AUTOSAR XML (schema 4-2-2)
package /Components
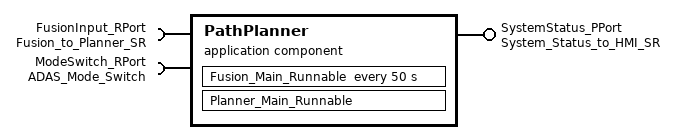
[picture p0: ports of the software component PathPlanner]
  application sw component type PathPlanner
    provide port SystemStatus_PPort: provided-interface=System_Status_to_HMI_SR
    provide/require port Actuation_ClientPort: provided-required-interface=Planner_to_Actuation_CS
    provide/require port Parameter_ClientPort: provided-required-interface=Parameter_Service_CS
    require port FusionInput_RPort: required-interface=Fusion_to_Planner_SR
    require port ModeSwitch_RPort: required-interface=ADAS_Mode_Switch
    behavior PathPlanner_Behavior
      external trigger occurred event Emergency_Brake_Trigger: start-on-event=Fusion_Main_Runnable
      swc mode switch event Mode_Switch_Requested: start-on-event=Fusion_Main_Runnable, activation=onModeRequest, mode=ADASModeGroup.ModeSwitch_RPort.ADASModeDeclaration
      timing event Planner_Cycle: start-on-event=Fusion_Main_Runnable, period=50
      runnable Planner_Main_Runnable: minimum-start-interval=25, symbol=PathPlanner_Planner_Main
        data-receive-point-by-values:
          access Access_FusedObjectList: accessed-variable=FusionInput_RPort.FusedObjectList
          access Access_ModeInfo: accessed-variable=ModeSwitch_RPort.ADAS_Mode
        data-send-points:
          access Send_ControlCommand: accessed-variable=SystemStatus_PPort.ControlCommand
        sync call Call_Actuation_SendCommand: called-from-within-exclusive-area=PlannerEA, operation=Actuation_ClientPort.SendCommand, timeout=100
